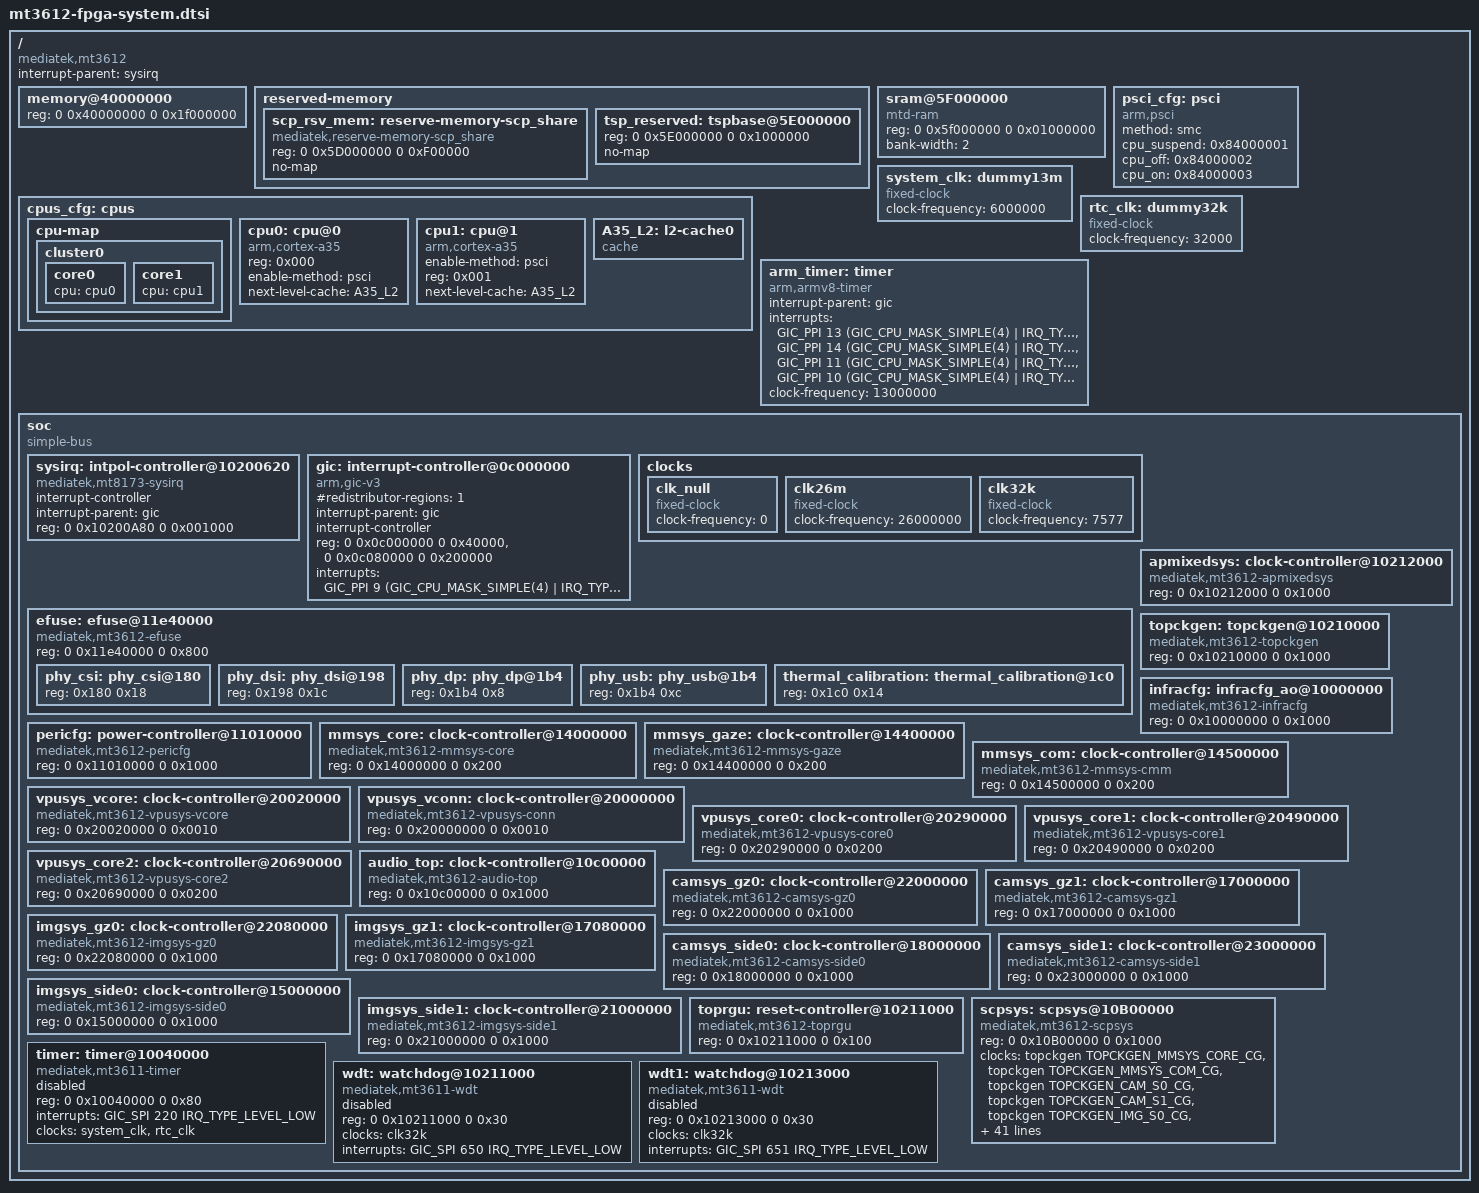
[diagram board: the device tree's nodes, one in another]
/*
 * Copyright (c) 2018 MediaTek Inc.
 * Author: Yung-Chi Chen <yung-chi.chen@mediatek.com>
 *
 * This program is free software; you can redistribute it and/or modify
 * it under the terms of the GNU General Public License version 2 as
 * published by the Free Software Foundation.
 *
 * This program is distributed in the hope that it will be useful,
 * but WITHOUT ANY WARRANTY; without even the implied warranty of
 * MERCHANTABILITY or FITNESS FOR A PARTICULAR PURPOSE.  See the
 * GNU General Public License for more details.
 */

#include <dt-bindings/interrupt-controller/arm-gic.h>
#include <dt-bindings/clock/mt3612-clk.h>
#include <dt-bindings/reset-controller/mt3612-resets.h>
#include <dt-bindings/power/mt3612-power.h>

/ {
	compatible = "mediatek,mt3612";
	interrupt-parent = <&sysirq>;
	#address-cells = <2>;
	#size-cells = <2>;


	memory@40000000 {
		device_type = "memory";
		reg = <0 0x40000000 0 0x1f000000>;
	};

	reserved-memory {
		#address-cells = <2>;
		#size-cells = <2>;
		ranges;

		scp_rsv_mem: reserve-memory-scp_share {
			compatible = "mediatek,reserve-memory-scp_share";
			reg = <0 0x5D000000 0 0xF00000>;
			no-map;
		};

		tsp_reserved: tspbase@5E000000 {
			reg = <0 0x5E000000 0 0x1000000>;
			no-map;
		};

	};


	sram@5F000000 {
		compatible = "mtd-ram";
		reg = <0 0x5f000000 0 0x01000000>;
		bank-width = <2>;
		status = "okay";
	};

	psci_cfg: psci {
		compatible = "arm,psci";
		method = "smc";
		cpu_suspend   = <0x84000001>;
		cpu_off	      = <0x84000002>;
		cpu_on	      = <0x84000003>;
	};

	cpus_cfg: cpus {
		#address-cells = <1>;
		#size-cells = <0>;

		cpu-map {
			cluster0 {
				core0 {
					cpu = <&cpu0>;
				};
				core1 {
					cpu = <&cpu1>;
				};
			};
		};

		cpu0: cpu@0 {
			device_type = "cpu";
			compatible = "arm,cortex-a35";
			reg = <0x000>;
			enable-method = "psci";
			next-level-cache = <&A35_L2>;
		};

		cpu1: cpu@1 {
			device_type = "cpu";
			compatible = "arm,cortex-a35";
			enable-method = "psci";
			reg = <0x001>;
			next-level-cache = <&A35_L2>;
		};

		A35_L2: l2-cache0 {
			compatible = "cache";
		};
	};

	system_clk: dummy13m {
		compatible = "fixed-clock";
		clock-frequency = <6000000>;
		#clock-cells = <0>;
	};

	rtc_clk: dummy32k {
		compatible = "fixed-clock";
		clock-frequency = <32000>;
		#clock-cells = <0>;
	};

	arm_timer: timer {
		compatible = "arm,armv8-timer";
		interrupt-parent = <&gic>;
		interrupts = <GIC_PPI 13 (GIC_CPU_MASK_SIMPLE(4) | IRQ_TYPE_LEVEL_LOW)>, /*Secure Physical Timer Event*/
			<GIC_PPI 14 (GIC_CPU_MASK_SIMPLE(4) | IRQ_TYPE_LEVEL_LOW)>, /*Non-Secure Physical Timer Event*/
			<GIC_PPI 11 (GIC_CPU_MASK_SIMPLE(4) | IRQ_TYPE_LEVEL_LOW)>, /*Virtual Timer Event*/
			<GIC_PPI 10 (GIC_CPU_MASK_SIMPLE(4) | IRQ_TYPE_LEVEL_LOW)>; /*Hypervisor Timer Event*/
			clock-frequency = <13000000>;
	};

	soc {
		#address-cells = <2>;
		#size-cells = <2>;
		compatible = "simple-bus";
		ranges;



		sysirq: intpol-controller@10200620 {
			compatible = "mediatek,mt8173-sysirq",
				     "mediatek,mt6577-sysirq";
			interrupt-controller;
			#interrupt-cells = <3>;
			interrupt-parent = <&gic>;
			reg = <0 0x10200A80 0 0x001000>;
		};

		gic: interrupt-controller@0c000000 {
			compatible = "arm,gic-v3";
			#interrupt-cells = <3>;
			#address-cells = <2>;
			#size-cells = <2>;
			#redistributor-regions = <1>;
			interrupt-parent = <&gic>;
			interrupt-controller;
			reg = <0 0x0c000000 0 0x40000>,
			      <0 0x0c080000 0 0x200000>;
			interrupts = <GIC_PPI 9 (GIC_CPU_MASK_SIMPLE(4) | IRQ_TYPE_LEVEL_HIGH)>;
		};


		clocks {
			clk_null: clk_null {
				compatible = "fixed-clock";
				#clock-cells = <0>;
				clock-frequency = <0>;
			};

			clk26m: clk26m {
				compatible = "fixed-clock";
				#clock-cells = <0>;
				clock-frequency = <26000000>;
			};

			clk32k: clk32k {
				compatible = "fixed-clock";
				#clock-cells = <0>;
				clock-frequency = <7577>;
			};
		};

		efuse: efuse@11e40000 {
			compatible = "mediatek,mt3612-efuse";
			reg = <0 0x11e40000 0 0x800>;
			#address-cells = <1>;
			#size-cells = <1>;
			phy_csi: phy_csi@180 {
				reg = <0x180 0x18>;
			};
			phy_dsi: phy_dsi@198 {
				reg = <0x198 0x1c>;
			};
			phy_dp: phy_dp@1b4 {
				reg = <0x1b4 0x8>;
			};
			phy_usb: phy_usb@1b4 {
				reg = <0x1b4 0xc>;
			};
			thermal_calibration: thermal_calibration@1c0 {
				reg = <0x1c0 0x14>;
			};
		};

		apmixedsys: clock-controller@10212000 {
			compatible = "mediatek,mt3612-apmixedsys";
			reg = <0 0x10212000 0 0x1000>;
			#clock-cells = <1>;
		};

		topckgen: topckgen@10210000 {
			compatible = "mediatek,mt3612-topckgen", "syscon";
			reg = <0 0x10210000 0 0x1000>;
			#clock-cells = <1>;
		};

		infracfg: infracfg_ao@10000000 {
			compatible = "mediatek,mt3612-infracfg", "syscon";
			reg = <0 0x10000000 0 0x1000>;
			#clock-cells = <1>;
			#reset-cells = <1>;
		};

		pericfg: power-controller@11010000 {
			compatible = "mediatek,mt3612-pericfg", "syscon";
			reg = <0 0x11010000 0 0x1000>;
			#clock-cells = <1>;
			#reset-cells = <1>;
		};

		mmsys_core: clock-controller@14000000 {
			compatible = "mediatek,mt3612-mmsys-core", "syscon";
			reg = <0 0x14000000 0 0x200>;
			#clock-cells = <1>;
		};

		mmsys_gaze: clock-controller@14400000 {
			compatible = "mediatek,mt3612-mmsys-gaze", "syscon";
			reg = <0 0x14400000 0 0x200>;
			#clock-cells = <1>;
		};

		mmsys_com: clock-controller@14500000 {
			compatible = "mediatek,mt3612-mmsys-cmm", "syscon";
			reg = <0 0x14500000 0 0x200>;
			#clock-cells = <1>;
		};

		vpusys_vcore: clock-controller@20020000 {
			compatible = "mediatek,mt3612-vpusys-vcore", "syscon";
			reg = <0 0x20020000 0 0x0010>;
			#clock-cells = <1>;
		};
		vpusys_vconn: clock-controller@20000000 {
			compatible = "mediatek,mt3612-vpusys-conn", "syscon";
			reg = <0 0x20000000 0 0x0010>;
			#clock-cells = <1>;
		};
		vpusys_core0: clock-controller@20290000 {
			compatible = "mediatek,mt3612-vpusys-core0", "syscon";
			reg = <0 0x20290000 0 0x0200>;
			#clock-cells = <1>;
		};
		vpusys_core1: clock-controller@20490000 {
			compatible = "mediatek,mt3612-vpusys-core1", "syscon";
			reg = <0 0x20490000 0 0x0200>;
			#clock-cells = <1>;
		};
		vpusys_core2: clock-controller@20690000 {
			compatible = "mediatek,mt3612-vpusys-core2", "syscon";
			reg = <0 0x20690000 0 0x0200>;
			#clock-cells = <1>;
		};
		audio_top: clock-controller@10c00000 {
			compatible = "mediatek,mt3612-audio-top", "syscon";
			reg = <0 0x10c00000 0 0x1000>;
			#clock-cells = <1>;
		};

		camsys_gz0: clock-controller@22000000 {
			compatible = "mediatek,mt3612-camsys-gz0", "syscon";
			reg = <0 0x22000000 0 0x1000>;
			#clock-cells = <1>;
		};

		camsys_gz1: clock-controller@17000000 {
			compatible = "mediatek,mt3612-camsys-gz1", "syscon";
			reg = <0 0x17000000 0 0x1000>;
			#clock-cells = <1>;
		};

		imgsys_gz0: clock-controller@22080000 {
			compatible = "mediatek,mt3612-imgsys-gz0", "syscon";
			reg = <0 0x22080000 0 0x1000>;
			#clock-cells = <1>;
		};

		imgsys_gz1: clock-controller@17080000 {
			compatible = "mediatek,mt3612-imgsys-gz1", "syscon";
			reg = <0 0x17080000 0 0x1000>;
			#clock-cells = <1>;
		};

		camsys_side0: clock-controller@18000000 {
			compatible = "mediatek,mt3612-camsys-side0", "syscon";
			reg = <0 0x18000000 0 0x1000>;
			#clock-cells = <1>;
		};

		camsys_side1: clock-controller@23000000 {
			compatible = "mediatek,mt3612-camsys-side1", "syscon";
			reg = <0 0x23000000 0 0x1000>;
			#clock-cells = <1>;
		};

		imgsys_side0: clock-controller@15000000 {
			compatible = "mediatek,mt3612-imgsys-side0", "syscon";
			reg = <0 0x15000000 0 0x1000>;
			#clock-cells = <1>;
		};

		imgsys_side1: clock-controller@21000000 {
			compatible = "mediatek,mt3612-imgsys-side1", "syscon";
			reg = <0 0x21000000 0 0x1000>;
			#clock-cells = <1>;
		};

		toprgu: reset-controller@10211000 {
			compatible = "mediatek,mt3612-toprgu", "syscon";
			reg = <0 0x10211000 0 0x100>;
			#reset-cells = <1>;
		};

		scpsys: scpsys@10B00000 {
			compatible = "mediatek,mt3612-scpsys";
			#power-domain-cells = <1>;
			reg = <0 0x10B00000 0 0x1000>;
			clocks = <&topckgen TOPCKGEN_MMSYS_CORE_CG>,
				<&topckgen TOPCKGEN_MMSYS_COM_CG>,
				<&topckgen TOPCKGEN_CAM_S0_CG>,
				<&topckgen TOPCKGEN_CAM_S1_CG>,
				<&topckgen TOPCKGEN_IMG_S0_CG>,
				<&topckgen TOPCKGEN_IMG_S1_CG>,
				<&topckgen TOPCKGEN_CAM_GZ0_CG>,
				<&topckgen TOPCKGEN_CAM_GZ1_CG>,
				<&topckgen TOPCKGEN_MM_SYSRAM2_CG>,
				<&topckgen TOPCKGEN_MM_SYSRAM1_CG>,
				<&topckgen TOPCKGEN_MM_SYSRAM0_CG>,
				<&topckgen TOPCKGEN_F26M_DP_REF_CK_EN>,
				<&topckgen TOPCKGEN_IPU_IF_CG>,
				<&topckgen TOPCKGEN_DSP_CG>,
				<&topckgen TOPCKGEN_DSP1_CG>,
				<&topckgen TOPCKGEN_DSP2_CG>,
				<&topckgen TOPCKGEN_DSP3_CG>,
				<&topckgen TOPCKGEN_MFG_CG>,
				<&mmsys_core MMSYS_CORE_LARB0_GALS>,
				<&mmsys_core MMSYS_CORE_LARB1_GALS>,
				<&mmsys_core MMSYS_CORE_LARB15_GALS>,
				<&mmsys_core MMSYS_CORE_LARB16_GALS>,
				<&mmsys_core MMSYS_CORE_SMI_LARB0>,
				<&mmsys_core MMSYS_CORE_SMI_LARB1>,
				<&mmsys_core MMSYS_CORE_SMI_LARB15>,
				<&mmsys_core MMSYS_CORE_SMI_LARB16>,
				<&mmsys_com MMSYS_CMM_SMI_COMMON>,
				<&mmsys_com MMSYS_CMM_SMI_LARB3>,
				<&mmsys_com MMSYS_CMM_SMI_LARB21>,
				<&mmsys_com MMSYS_CMM_SMI_LARB2>,
				<&mmsys_com MMSYS_CMM_SMI_LARB20>,
				<&mmsys_gaze MMSYS_GAZE_SMI_LARB4>,
				<&mmsys_gaze MMSYS_GAZE_SMI_LARB22>,
				<&camsys_side0 CAMSYS_SIDE0_SYSRAM_LARBX_CGPDN>,
				<&camsys_side0 CAMSYS_SIDE0_LARBX_CGPDN>,
				<&camsys_side1 CAMSYS_SIDE1_SYSRAM_LARBX_CGPDN>,
				<&camsys_side1 CAMSYS_SIDE1_LARBX_CGPDN>,
				<&imgsys_side0 IMGSYS_SIDE0_SYSRAM_LARBX_CGPDN>,
				<&imgsys_side0 IMGSYS_SIDE0_LARBX_CGPDN>,
				<&imgsys_side1 IMGSYS_SIDE1_SYSRAM_LARBX_CGPDN>,
				<&imgsys_side1 IMGSYS_SIDE1_LARBX_CGPDN>,
				<&camsys_gz0 CAMSYS_GZ0_SYSRAM_LARBX_CGPDN>,
				<&camsys_gz0 CAMSYS_GZ0_LARBX_CGPDN>,
				<&camsys_gz1 CAMSYS_GZ1_SYSRAM_LARBX_CGPDN>,
				<&camsys_gz1 CAMSYS_GZ1_LARBX_CGPDN>;
			clock-names = "mm_core", "mm_cmm",
				"cam_side0", "cam_side1",
				"img_side0", "img_side1",
				"cam_img_gz0", "cam_img_gz1",
				"mm_sysram2", "mm_sysram1",
				"mm_sysram0", "dp",
				"ipu_if", "dsp",
				"dsp1", "dsp2",
				"dsp3",	"mfg",
				"mm-core-larb0", "mm-core-larb1",
				"mm-core-larb15", "mm-core-larb16",
				"mm-core-smi0",	"mm-core-smi1",
				"mm-core-smi15", "mm-core-smi16",
				"mm-cmm-smi-com", "mm-cmm-smi3",
				"mm-cmm-smi21",	"mm-cmm-smi2",
				"mm-cmm-smi20", "mm-gaze-smi4",
				"mm-gaze-smi22", "cam-s0-sysram-larb",
				"cam-s0-larb", "cam-s1-sysram-larb",
				"cam-s1-larb", "img-s0-sysram-larb",
				"img-s0-larb", "img-s1-sysram-larb",
				"img-s1-larb", "cam-gz0-sysram-larb",
				"cam-gz0-larb",	"cam-gz1-sysram-larb",
				"cam-gz1-larb";
			infracfg = <&infracfg>;
			/*status = "disable";*/
		};


		timer: timer@10040000 {
			compatible = "mediatek,mt3611-timer",
				     "mediatek,mt6577-timer";
			reg = <0 0x10040000 0 0x80>;
			interrupts = <GIC_SPI 220 IRQ_TYPE_LEVEL_LOW>;
			clocks = <&system_clk>, <&rtc_clk>;
			clock-names = "system-clk", "rtc-clk";
			status = "disabled";
		};

		wdt: watchdog@10211000 {
			compatible = "mediatek,mt3611-wdt";
			reg = <0 0x10211000 0 0x30>;
			clocks = <&clk32k>;
			clock-names = "wdtclksrc";
			interrupts = <GIC_SPI 650 IRQ_TYPE_LEVEL_LOW>;
			status = "disabled";
		};

		wdt1: watchdog@10213000 {
			compatible = "mediatek,mt3611-wdt";
			reg = <0 0x10213000 0 0x30>;
			clocks = <&clk32k>;
			clock-names = "wdtclksrc";
			interrupts = <GIC_SPI 651 IRQ_TYPE_LEVEL_LOW>;
			status = "disabled";
		};

	};
};

